# MCXA156 register map
Vendor: nxp.com; File version: 1.0
CPU: CM33 r2p0, little endian, no MPU, FPU, VTOR, 3 interrupt priority bits
Registers are 32-bit, read-write, reset 0x0 unless marked. A register's access mark holds for its fields unless they carry their own. Offsets are from the block's base; [hi:lo] are bit positions; 'fields as' and 'values as' point back to an identical list.

## LPI2C0 — Low-Power Inter-Integrated Circuit
Base 0x4009A000
Same registers: LPI2C1 0x4009B000, LPI2C2 0x400D4000, LPI2C3 0x400D5000
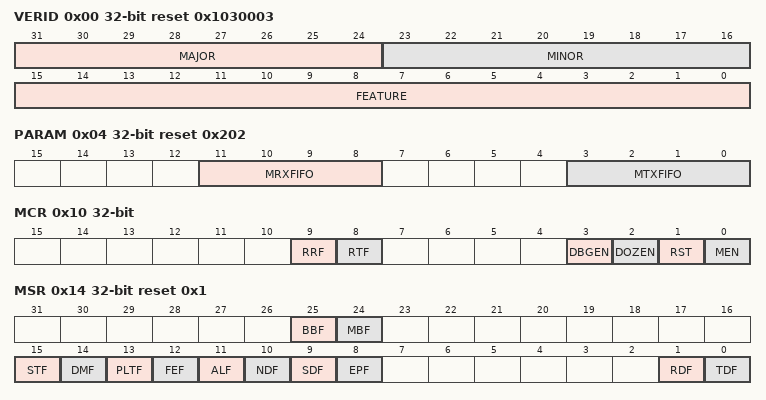
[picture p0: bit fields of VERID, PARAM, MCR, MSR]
0x00 VERID ro reset 0x1030003 — Version ID
  [31:24] MAJOR — Major Version Number
  [23:16] MINOR — Minor Version Number
  [15:0] FEATURE — Feature Specification Number
    2=MASTER_ONLY (Controller only, with standard feature set); 3=MASTER_AND_SLAVE (Controller and target, with standard feature set)
0x04 PARAM ro reset 0x202 — Parameter
  [11:8] MRXFIFO — Controller Receive FIFO Size
  [3:0] MTXFIFO — Controller Transmit FIFO Size
0x10 MCR — Controller Control
  [9] RRF — Reset Receive FIFO
    0=NO_EFFECT; 1=RESET (Reset receive FIFO)
  [8] RTF — Reset Transmit FIFO
    0=NO_EFFECT; 1=RESET (Reset transmit FIFO)
  [3] DBGEN — Debug Enable
    0=DISABLED; 1=ENABLED
  [2] DOZEN — Doze Mode Enable
    0=ENABLED; 1=DISABLED
  [1] RST — Software Reset
    0=NOT_RESET (No effect); 1=RESET
  [0] MEN — Controller Enable
    0=DISABLED; 1=ENABLED
0x14 MSR reset 0x1 — Controller Status
  [25] BBF ro — Bus Busy Flag
    0=IDLE; 1=BUSY
  [24] MBF ro — Controller Busy Flag
    0=IDLE; 1=BUSY
  [15] STF write-1-clears — Start Flag
    on read: 0=INT_NO (Start condition not detected); 1=INT_YES (Start condition detected)
  [14] DMF write-1-clears — Data Match Flag
    on read: 0=INT_NO (Matching data not received); 1=INT_YES (Matching data received)
  [13] PLTF write-1-clears — Pin Low Timeout Flag
    on read: 0=INT_NO (Pin low timeout did not occur); 1=INT_YES (Pin low timeout occurred)
  [12] FEF write-1-clears — FIFO Error Flag
    on read: 0=INT_NO (No FIFO error); 1=INT_YES (FIFO error)
  [11] ALF write-1-clears — Arbitration Lost Flag
    on read: 0=INT_NO (Controller did not lose arbitration); 1=INT_YES (Controller lost arbitration)
  [10] NDF write-1-clears — NACK Detect Flag
    on read: 0=INT_NO (No unexpected NACK detected); 1=INT_YES (Unexpected NACK detected)
  [9] SDF write-1-clears — Stop Detect Flag
    on read: 0=INT_NO (No Stop condition generated); 1=INT_YES (Stop condition generated)
  [8] EPF write-1-clears — End Packet Flag
    on read: 0=INT_NO (No Stop or repeated Start generated); 1=INT_YES (Stop or repeated Start generated)
  [1] RDF ro — Receive Data Flag
    0=DISABLED (Receive data not ready); 1=ENABLED (Receive data ready)
  [0] TDF ro — Transmit Data Flag
    0=DISABLED (Transmit data not requested); 1=ENABLED (Transmit data requested)
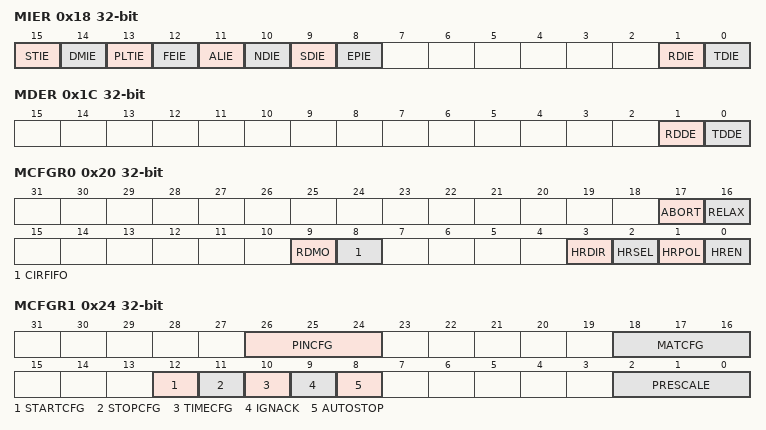
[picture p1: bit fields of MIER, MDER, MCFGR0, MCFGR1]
0x18 MIER — Controller Interrupt Enable
  [all] fields
    0=DISABLED; 1=ENABLED
  [15] STIE — Start Interrupt Enable
  [14] DMIE — Data Match Interrupt Enable
  [13] PLTIE — Pin Low Timeout Interrupt Enable
  [12] FEIE — FIFO Error Interrupt Enable
  [11] ALIE — Arbitration Lost Interrupt Enable
  [10] NDIE — NACK Detect Interrupt Enable
  [9] SDIE — Stop Detect Interrupt Enable
  [8] EPIE — End Packet Interrupt Enable
  [1] RDIE — Receive Data Interrupt Enable
  [0] TDIE — Transmit Data Interrupt Enable
0x1C MDER — Controller DMA Enable
  [1] RDDE — Receive Data DMA Enable
    0=DISABLED; 1=ENABLED
  [0] TDDE — Transmit Data DMA Enable
    0=DISABLED; 1=ENABLED
0x20 MCFGR0 — Controller Configuration 0
  [17] ABORT — Abort Transfer
    0=DISABLED (Normal transfer); 1=ENABLED (Abort existing transfer and do not start a new one)
  [16] RELAX — Relaxed Mode
    0=NORMAL_TRANSFER; 1=RELAXED_TRANSFER
  [9] RDMO — Receive Data Match Only
    0=DISABLED (Received data is stored in the receive FIFO); 1=ENABLED (Received data is discarded unless MSR[DMF] is set)
  [8] CIRFIFO — Circular FIFO Enable
    0=DISABLED; 1=ENABLED
  [3] HRDIR — Host Request Direction
    0=INPUT (HREQ pin is input (for LPI2C controller)); 1=OUTPUT (HREQ pin is output (for LPI2C target))
  [2] HRSEL — Host Request Select
    0=DISABLED (Host request input is pin HREQ); 1=ENABLED (Host request input is input trigger)
  [1] HRPOL — Host Request Polarity
    0=ACTIVE_LOW; 1=ACTIVE_HIGH
  [0] HREN — Host Request Enable
    0=DISABLED; 1=ENABLED
0x24 MCFGR1 — Controller Configuration 1
  [26:24] PINCFG — Pin Configuration
    0=OPEN_DRAIN_2_PIN (Two-pin open drain mode); 1=OUTPUT_2_PIN_ONLY (Two-pin output only mode (Ultra-Fast mode)); 2=PUSH_PULL_2_PIN (Two-pin push-pull mode); 3=PUSH_PULL_4_PIN (Four-pin push-pull mode); 4=OPEN_DRAIN_2_PIN_W_LPI2C_SLAVE (Two-pin open-drain mode with separate LPI2C target); 5=OUTPUT_2_PIN_ONLY_W_LPI2C_SLAVE (Two-pin output only mode (Ultra-Fast mode) with separate LPI2C target); 6=PUSH_PULL_2_PIN_W_LPI2C_SLAVE (Two-pin push-pull mode with separate LPI2C target); 7=PUSH_PULL_4_PIN_W_LPI2C_SLAVE (Four-pin push-pull mode (inverted outputs))
  [18:16] MATCFG — Match Configuration
    0=DISABLED (Match is disabled); 2=FIRST_DATA_WORD_EQUALS_MATCH0_OR_MATCH1 (Match is enabled: first data word equals MDMR[MATCH0] OR MDMR[MATCH1]); 3=ANY_DATA_WORD_EQUALS_MATCH0_OR_MATCH1 (Match is enabled: any data word equals MDMR[MATCH0] OR MDMR[MATCH1]); 4=FIRST_DATA_WORD_MATCH0_AND_SECOND_DATA_WORD_MATCH1 (Match is enabled: (first data word equals MDMR[MATCH0]) AND (second data word equals MDMR[MATCH1)); 5=ANY_DATA_WORD_MATCH0_NEXT_DATA_WORD_MATCH1 (Match is enabled: (any data word equals MDMR[MATCH0]) AND (next data word equals MDMR[MATCH1)); 6=FIRST_DATA_WORD_AND_MATCH1_EQUALS_MATCH0_AND_MATCH1 (Match is enabled: (first data word AND MDMR[MATCH1]) equals (MDMR[MATCH0] AND MDMR[MATCH1])); 7=ANY_DATA_WORD_AND_MATCH1_EQUALS_MATCH0_AND_MATCH1 (Match is enabled: (any data word AND MDMR[MATCH1]) equals (MDMR[MATCH0] AND MDMR[MATCH1]))
  [12] STARTCFG — Start Configuration
    0=BOTH_I2C_AND_LPI2C_IDLE (Sets when both I2C bus and LPI2C controller are idle); 1=I2C_IDLE (Sets when I2C bus is idle)
  [11] STOPCFG — Stop Configuration
    0=ANY_STOP (Any Stop condition); 1=LAST_STOP (Last Stop condition)
  [10] TIMECFG — Timeout Configuration
    0=IF_SCL_LOW (SCL); 1=IF_SCL_OR_SDA_LOW (SCL or SDA)
  [9] IGNACK — Ignore NACK
    0=DISABLED (No effect); 1=ENABLED (Treat a received NACK as an ACK)
  [8] AUTOSTOP — Automatic Stop Generation
    0=DISABLED (No effect); 1=ENABLED (Stop automatically generated)
  [2:0] PRESCALE — Prescaler
    0=DIVIDE_BY_1; 1=DIVIDE_BY_2; 2=DIVIDE_BY_4; 3=DIVIDE_BY_8; 4=DIVIDE_BY_16; 5=DIVIDE_BY_32; 6=DIVIDE_BY_64; 7=DIVIDE_BY_128
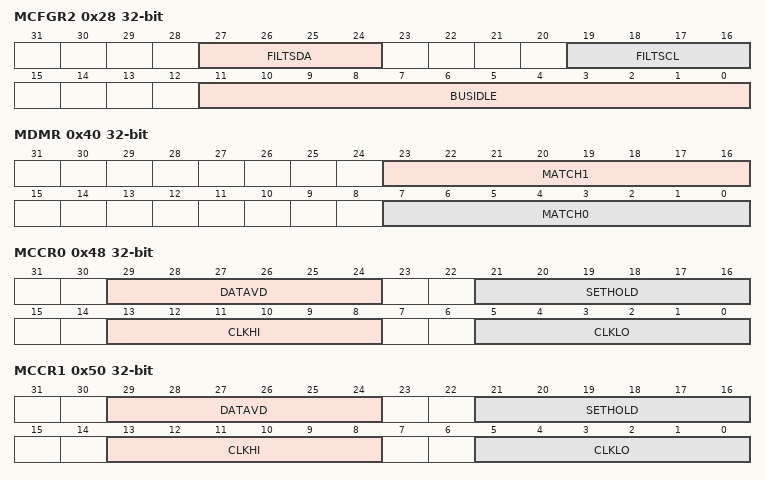
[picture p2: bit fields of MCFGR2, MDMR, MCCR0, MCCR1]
0x28 MCFGR2 — Controller Configuration 2
  [27:24] FILTSDA — Glitch Filter SDA
  [19:16] FILTSCL — Glitch Filter SCL
  [11:0] BUSIDLE — Bus Idle Timeout
0x2C MCFGR3 — Controller Configuration 3
  [19:8] PINLOW — Pin Low Timeout
0x40 MDMR — Controller Data Match
  [23:16] MATCH1 — Match 1 Value
  [7:0] MATCH0 — Match 0 Value
0x48 MCCR0 — Controller Clock Configuration 0
  [29:24] DATAVD — Data Valid Delay
  [21:16] SETHOLD — Setup Hold Delay
  [13:8] CLKHI — Clock High Period
  [5:0] CLKLO — Clock Low Period
0x50 MCCR1 — Controller Clock Configuration 1
  fields as MCCR0
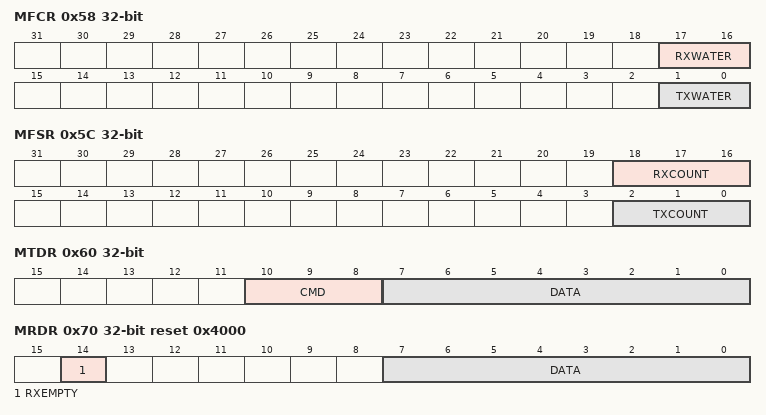
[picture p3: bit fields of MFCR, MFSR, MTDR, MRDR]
0x58 MFCR — Controller FIFO Control
  [17:16] RXWATER — Receive FIFO Watermark
  [1:0] TXWATER — Transmit FIFO Watermark
0x5C MFSR ro — Controller FIFO Status
  [18:16] RXCOUNT — Receive FIFO Count
  [2:0] TXCOUNT — Transmit FIFO Count
0x60 MTDR wo — Controller Transmit Data
  [10:8] CMD — Command Data
    0=TRANSMIT_DATA_7_THROUGH_0 (Transmit the value in DATA[7:0]); 1=RECEIVE_DATA_7_THROUGH_0_PLUS_ONE (Receive (DATA[7:0] + 1) bytes); 2=GENERATE_STOP_CONDITION (Generate Stop condition on I2C bus); 3=RECEIVE_AND_DISCARD_DATA_7_THROUGH_0_PLUS_ONE (Receive and discard (DATA[7:0] + 1) bytes); 4=GENERATE_START_AND_TRANSMIT_ADDRESS_IN_DATA_7_THROUGH_0 (Generate (repeated) Start on the I2C bus and transmit the address in DATA[7:0]); 5=GENERATE_START_AND_TRANSMIT_ADDRESS_IN_DATA_7_THROUGH_0_EXPECT_NACK (Generate (repeated) Start on the I2C bus and transmit the address in DATA[7:0] (this transfer expects a NACK to be returned)); 6=GENERATE_START_AND_TRANSMIT_ADDRESS_IN_DATA_7_THROUGH_0_USING_HIGH_SPEED_MODE (Generate (repeated) Start on the I2C bus and transmit the address in DATA[7:0] using HS mode); 7=GENERATE_START_AND_TRANSMIT_ADDRESS_IN_DATA_7_THROUGH_0_USING_HIGH_SPEED_MODE_EXPECT_NACK (Generate (repeated) Start on the I2C bus and transmit the address in DATA[7:0] using HS mode (this transfer expects a NACK to be returned))
  [7:0] DATA — Transmit Data
0x70 MRDR ro reset 0x4000 — Controller Receive Data
  [14] RXEMPTY — Receive Empty
    0=NOT_EMPTY; 1=EMPTY
  [7:0] DATA — Receive Data
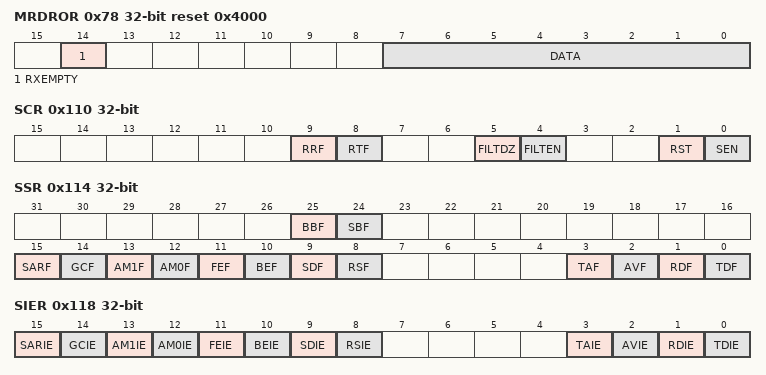
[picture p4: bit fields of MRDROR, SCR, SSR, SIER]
0x78 MRDROR ro reset 0x4000 — Controller Receive Data Read Only
  [14] RXEMPTY
    0=NOT_EMPTY; 1=EMPTY
  [7:0] DATA — Receive Data
0x110 SCR — Target Control
  [9] RRF — Reset Receive FIFO
    0=NO_EFFECT; 1=NOW_EMPTY (SRDR is now empty)
  [8] RTF — Reset Transmit FIFO
    0=NO_EFFECT; 1=NOW_EMPTY (STDR is now empty)
  [5] FILTDZ — Filter Doze Enable
    0=FILTER_ENABLED (Enable); 1=FILTER_DISABLED (Disable)
  [4] FILTEN — Filter Enable
    0=DISABLE; 1=ENABLE
  [1] RST — Software Reset
    0=NOT_RESET; 1=RESET
  [0] SEN — Target Enable
    0=DISABLED; 1=ENABLED
0x114 SSR — Target Status
  [25] BBF ro — Bus Busy Flag
    0=IDLE; 1=BUSY
  [24] SBF ro — Target Busy Flag
    0=IDLE; 1=BUSY
  [15] SARF ro — SMBus Alert Response Flag
    0=NO_FLAG (Disabled or not detected); 1=FLAG (Enabled and detected)
  [14] GCF ro — General Call Flag
    0=NO_FLAG (General call address disabled or not detected); 1=FLAG (General call address detected)
  [13] AM1F ro — Address Match 1 Flag
    0=NO_FLAG (Matching address not received); 1=FLAG (Matching address received)
  [12] AM0F ro — Address Match 0 Flag
    0=NO_FLAG (ADDR0 matching address not received); 1=FLAG (ADDR0 matching address received)
  [11] FEF write-1-clears — FIFO Error Flag
    on read: 0=INT_NO (No FIFO error); 1=INT_YES (FIFO error)
  [10] BEF write-1-clears — Bit Error Flag
    on read: 0=INT_NO (No bit error occurred); 1=INT_YES (Bit error occurred)
  [9] SDF write-1-clears — Stop Detect Flag
    on read: 0=INT_NO (No Stop detected); 1=INT_YES (Stop detected)
  [8] RSF write-1-clears — Repeated Start Flag
    on read: 0=INT_NO (No repeated Start detected); 1=INT_YES (Repeated Start detected)
  [3] TAF ro — Transmit ACK Flag
    0=NOT_REQUIRED; 1=REQUIRED
  [2] AVF ro — Address Valid Flag
    0=NOT_VALID; 1=VALID
  [1] RDF ro — Receive Data Flag
    0=NOT_READY; 1=READY
  [0] TDF ro — Transmit Data Flag
    0=NO_FLAG (Transmit data not requested); 1=FLAG (Transmit data is requested)
0x118 SIER — Target Interrupt Enable
  [all] fields
    0=DISABLED; 1=ENABLED
  [15] SARIE — SMBus Alert Response Interrupt Enable
  [14] GCIE — General Call Interrupt Enable
  [13] AM1IE — Address Match 1 Interrupt Enable
  [12] AM0IE — Address Match 0 Interrupt Enable
  [11] FEIE — FIFO Error Interrupt Enable
  [10] BEIE — Bit Error Interrupt Enable
  [9] SDIE — Stop Detect Interrupt Enable
  [8] RSIE — Repeated Start Interrupt Enable
  [3] TAIE — Transmit ACK Interrupt Enable
  [2] AVIE — Address Valid Interrupt Enable
  [1] RDIE — Receive Data Interrupt Enable
  [0] TDIE — Transmit Data Interrupt Enable
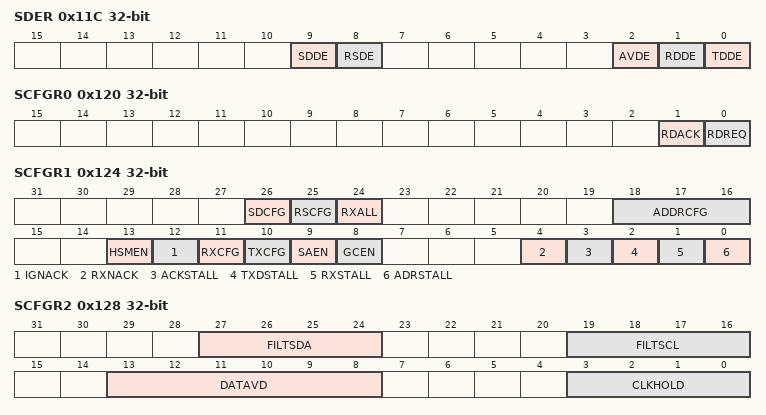
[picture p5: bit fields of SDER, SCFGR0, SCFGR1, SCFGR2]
0x11C SDER — Target DMA Enable
  [9] SDDE — Stop Detect DMA Enable
    0=DISABLED; 1=ENABLED
  [8] RSDE — Repeated Start DMA Enable
    0=DISABLED; 1=ENABLED
  [2] AVDE — Address Valid DMA Enable
    0=DISABLED; 1=ENABLED
  [1] RDDE — Receive Data DMA Enable
    0=DISABLED (Disable DMA request); 1=ENABLED (Enable DMA request)
  [0] TDDE — Transmit Data DMA Enable
    0=DISABLED; 1=ENABLED
0x120 SCFGR0 — Target Configuration 0
  [1] RDACK ro — Read Acknowledge Flag
    0=NOT_ACKNOWLEDGED (Read Request not acknowledged); 1=ACKNOWLEDGED (Read Request acknowledged)
  [0] RDREQ — Read Request
    0=DISABLED; 1=ENABLED
0x124 SCFGR1 — Target Configuration 1
  [26] SDCFG — Stop Detect Configuration
    0=ANY_STOP_AFTER_ADDRESS_MATCH (Any Stop condition following an address match); 1=ANY_STOP (Any Stop condition)
  [25] RSCFG — Repeated Start Configuration
    0=ANY_REPEATED_START_AFTER_ADDRESS_MATCH (Any repeated Start condition following an address match); 1=ANY_REPEATED_START (Any repeated Start condition)
  [24] RXALL — Receive All
    0=DISABLED; 1=ENABLED
  [18:16] ADDRCFG — Address Configuration
    0=ADDRESS_MATCH0_7_BIT; 1=ADDRESS_MATCH0_10_BIT; 2=ADDRESS_MATCH0_7_BIT_OR_ADDRESS_MATCH1_7_BIT; 3=ADDRESS_MATCH0_10_BIT_OR_ADDRESS_MATCH1_10_BIT; 4=ADDRESS_MATCH0_7_BIT_OR_ADDRESS_MATCH1_10_BIT; 5=ADDRESS_MATCH0_10_BIT_OR_ADDRESS_MATCH1_7_BIT; 6=FROM_ADDRESS_MATCH0_7_BIT_TO_ADDRESS_MATCH1_7_BIT; 7=FROM_ADDRESS_MATCH0_10_BIT_TO_ADDRESS_MATCH1_10_BIT
  [13] HSMEN — HS Mode Enable
    0=DISABLED; 1=ENABLED
  [12] IGNACK — Ignore NACK
    0=ENDS_TRANSFER_ON_NACK (End transfer on NACK); 1=DOES_NOT_END_TRANSFER_ON_NACK (Do not end transfer on NACK)
  [11] RXCFG — Receive Data Configuration
    0=RETURNS_RECEIVED_DATA_AND_CLEARS_RX_DATA_FLAG (Return received data, clear MSR[RDF]); 1=WHEN_ADDRESS_VALID_FLAG_SET_RETURNS_ADDRESS_STATUS_AND_CLEARS_ADDRESS_VALID_FLAG (Return SASR and clear SSR[AVF] when SSR[AVF] is set, return received data and clear MSR[RDF] when SSR[AFV] is not set)
  [10] TXCFG — Transmit Flag Configuration
    0=ASSERTS_DURING_SLAVE_TRANSMIT_TRANSFER_WHEN_TX_DATA_EMPTY (MSR[TDF] is set only during a target-transmit transfer when STDR is empty); 1=ASSERTS_WHEN_TX_DATA_EMPTY (MSR[TDF] is set whenever STDR is empty)
  [9] SAEN — SMBus Alert Enable
    0=DISABLE; 1=ENABLE
  [8] GCEN — General Call Enable
    0=DISABLED; 1=ENABLED
  [4] RXNACK — Receive NACK
    0=SET_BY_TXNACK (ACK or NACK always determined by STAR[TXNACK]); 1=ALWAYS_GENERATED_ON_ADDRESS_OR_RECEIVE_DATA_OVERRUN (NACK always generated on address overrun or receive data overrun, otherwise ACK or NACK is determined by STAR[TXNACK])
  [3] ACKSTALL — ACK SCL Stall
    0=DISABLED; 1=ENABLED
  [2] TXDSTALL — Transmit Data SCL Stall
    0=DISABLED; 1=ENABLED
  [1] RXSTALL — RX SCL Stall
    0=DISABLED; 1=ENABLED
  [0] ADRSTALL — Address SCL Stall
    0=DISABLED; 1=ENABLED
0x128 SCFGR2 — Target Configuration 2
  [27:24] FILTSDA — Glitch Filter SDA
  [19:16] FILTSCL — Glitch Filter SCL
  [13:8] DATAVD — Data Valid Delay
  [3:0] CLKHOLD — Clock Hold Time
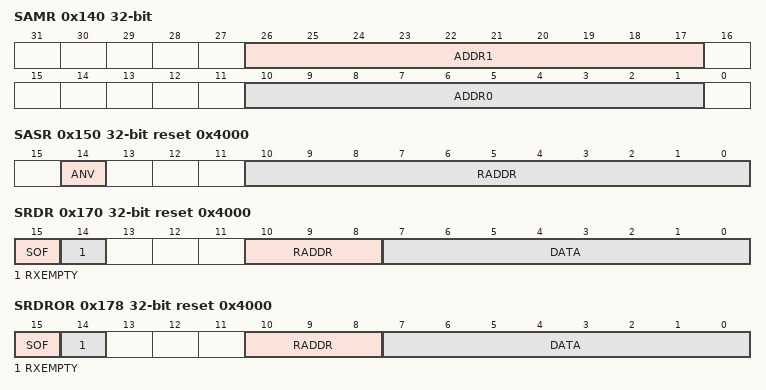
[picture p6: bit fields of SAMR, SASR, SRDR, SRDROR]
0x140 SAMR — Target Address Match
  [26:17] ADDR1 — Address 1 Value
  [10:1] ADDR0 — Address 0 Value
0x150 SASR ro reset 0x4000 — Target Address Status
  [14] ANV — Address Not Valid
    0=VALID; 1=NOT_VALID
  [10:0] RADDR — Received Address
0x154 STAR — Target Transmit ACK
  [0] TXNACK — Transmit NACK
    0=TRANSMIT_ACK; 1=TRANSMIT_NACK
0x160 STDR wo — Target Transmit Data
  [7:0] DATA — Transmit Data
0x170 SRDR ro reset 0x4000 — Target Receive Data
  [15] SOF — Start of Frame
    0=NOT_FIRST_DATA_WORD; 1=FIRST_DATA_WORD
  [14] RXEMPTY — Receive Empty
    0=NOT_EMPTY; 1=EMPTY
  [10:8] RADDR — Received Address
  [7:0] DATA — Received Data
0x178 SRDROR ro reset 0x4000 — Target Receive Data Read Only
  [15] SOF — Start of Frame
    0=NOT_FIRST_DATA_WORD (Not the first); 1=FIRST_DATA_WORD
  [14] RXEMPTY — Receive Empty
    0=NOT_EMPTY; 1=EMPTY
  [10:8] RADDR — Received Address
  [7:0] DATA — Receive Data
